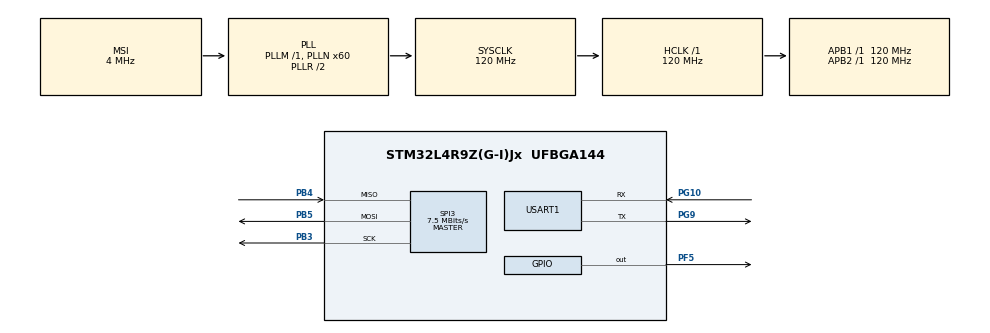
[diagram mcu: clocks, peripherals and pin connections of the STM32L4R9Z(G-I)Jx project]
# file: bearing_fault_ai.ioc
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Mcu.Family=STM32L4
Mcu.Name=STM32L4R9Z(G-I)Jx
Mcu.Package=UFBGA144
NVIC.PriorityGroup=NVIC_PRIORITYGROUP_4
NVIC.SPI3_IRQn=true\:0\:0\:false\:false\:true\:true\:true\:true
NVIC.USART1_IRQn=true\:0\:0\:false\:false\:true\:true\:true\:true
PA13\ (JTMS/SWDIO).Mode=Serial_Wire
PA13\ (JTMS/SWDIO).Signal=SYS_JTMS-SWDIO
PA14\ (JTCK/SWCLK).Mode=Serial_Wire
PA14\ (JTCK/SWCLK).Signal=SYS_JTCK-SWCLK
PB3\ (JTDO/TRACESWO).Mode=Full_Duplex_Master
PB3\ (JTDO/TRACESWO).Signal=SPI3_SCK
PB4\ (NJTRST).Mode=Full_Duplex_Master
PB4\ (NJTRST).Signal=SPI3_MISO
PB5.Mode=Full_Duplex_Master
PB5.Signal=SPI3_MOSI
PC14-OSC32_IN\ (PC14).Mode=LSE-External-Oscillator
PC14-OSC32_IN\ (PC14).Signal=RCC_OSC32_IN
PC15-OSC32_OUT\ (PC15).Mode=LSE-External-Oscillator
PC15-OSC32_OUT\ (PC15).Signal=RCC_OSC32_OUT
PF5.Signal=GPIO_Output
PG10.Mode=Asynchronous
PG10.Signal=USART1_RX
PG9.Mode=Asynchronous
PG9.Signal=USART1_TX
PH0-OSC_IN\ (PH0).Mode=HSE-External-Oscillator
PH0-OSC_IN\ (PH0).Signal=RCC_OSC_IN
PH1-OSC_OUT\ (PH1).Mode=HSE-External-Oscillator
PH1-OSC_OUT\ (PH1).Signal=RCC_OSC_OUT
ProjectManager.HeapSize=0x200
ProjectManager.StackSize=0x400
ProjectManager.TargetToolchain=STM32CubeIDE
RCC.AHBFreq_Value=120000000
RCC.APB1Freq_Value=120000000
RCC.APB1TimFreq_Value=120000000
RCC.APB2Freq_Value=120000000
RCC.APB2TimFreq_Value=120000000
RCC.CortexFreq_Value=120000000
RCC.HCLKFreq_Value=120000000
RCC.HSE_VALUE=8000000
RCC.HSI48_VALUE=48000000
RCC.HSI_VALUE=16000000
RCC.MSI_VALUE=4000000
RCC.PLLN=60
RCC.SYSCLKFreq_VALUE=120000000
RCC.SYSCLKSource=RCC_SYSCLKSOURCE_PLLCLK
RCC.VCOOutputFreq_Value=240000000
SPI3.BaudRatePrescaler=SPI_BAUDRATEPRESCALER_16
SPI3.CalculateBaudRate=7.5 MBits/s
SPI3.DataSize=SPI_DATASIZE_8BIT
SPI3.Direction=SPI_DIRECTION_2LINES
SPI3.Mode=SPI_MODE_MASTER
SPI3.NSSPMode=SPI_NSS_PULSE_DISABLE
SPI3.VirtualType=VM_MASTER
USART1.VirtualMode-Asynchronous=VM_ASYNC
board=custom

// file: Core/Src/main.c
/* USER CODE BEGIN Header */
/**
  ******************************************************************************
  * @file           : main.c
  * @brief          : Main program body
  ******************************************************************************
  * @attention
  *
  * Copyright (c) 2025 STMicroelectronics.
  * All rights reserved.
  *
  * This software is licensed under terms that can be found in the LICENSE file
  * in the root directory of this software component.
  * If no LICENSE file comes with this software, it is provided AS-IS.
  *
  ******************************************************************************
  */
/* USER CODE END Header */
#include "main.h"
#include "spi.h"
#include "usart.h"
#include "gpio.h"

void SystemClock_Config(void);

/* USER CODE BEGIN 0 */
void iis3dwb_read_data_polling(void);

/* USER CODE END 0 */

int main(void)
{

  /* MCU Configuration--------------------------------------------------------*/

  /* Reset of all peripherals, Initializes the Flash interface and the Systick. */
  HAL_Init();

  /* Configure the system clock */
  SystemClock_Config();

  /* Initialize all configured peripherals */
  MX_GPIO_Init();
  MX_SPI3_Init();
  MX_USART1_UART_Init();

  /* Infinite loop */
  /* USER CODE BEGIN WHILE */
  while (1)
  {
	  iis3dwb_read_data_polling();
    /* USER CODE END WHILE */

  }
}

void SystemClock_Config(void)
{
  RCC_OscInitTypeDef RCC_OscInitStruct = {0};
  RCC_ClkInitTypeDef RCC_ClkInitStruct = {0};

  /** Configure the main internal regulator output voltage
  */
  if (HAL_PWREx_ControlVoltageScaling(PWR_REGULATOR_VOLTAGE_SCALE1_BOOST) != HAL_OK)
  {
    Error_Handler();
  }

  /** Initializes the RCC Oscillators according to the specified parameters
  * in the RCC_OscInitTypeDef structure.
  */
  RCC_OscInitStruct.OscillatorType = RCC_OSCILLATORTYPE_MSI;
  RCC_OscInitStruct.MSIState = RCC_MSI_ON;
  RCC_OscInitStruct.MSICalibrationValue = 0;
  RCC_OscInitStruct.MSIClockRange = RCC_MSIRANGE_6;
  RCC_OscInitStruct.PLL.PLLState = RCC_PLL_ON;
  RCC_OscInitStruct.PLL.PLLSource = RCC_PLLSOURCE_MSI;
  RCC_OscInitStruct.PLL.PLLM = 1;
  RCC_OscInitStruct.PLL.PLLN = 60;
  RCC_OscInitStruct.PLL.PLLP = RCC_PLLP_DIV2;
  RCC_OscInitStruct.PLL.PLLQ = RCC_PLLQ_DIV2;
  RCC_OscInitStruct.PLL.PLLR = RCC_PLLR_DIV2;
  if (HAL_RCC_OscConfig(&RCC_OscInitStruct) != HAL_OK)
  {
    Error_Handler();
  }

  /** Initializes the CPU, AHB and APB buses clocks
  */
  RCC_ClkInitStruct.ClockType = RCC_CLOCKTYPE_HCLK|RCC_CLOCKTYPE_SYSCLK
                              |RCC_CLOCKTYPE_PCLK1|RCC_CLOCKTYPE_PCLK2;
  RCC_ClkInitStruct.SYSCLKSource = RCC_SYSCLKSOURCE_PLLCLK;
  RCC_ClkInitStruct.AHBCLKDivider = RCC_SYSCLK_DIV1;
  RCC_ClkInitStruct.APB1CLKDivider = RCC_HCLK_DIV1;
  RCC_ClkInitStruct.APB2CLKDivider = RCC_HCLK_DIV1;

  if (HAL_RCC_ClockConfig(&RCC_ClkInitStruct, FLASH_LATENCY_5) != HAL_OK)
  {
    Error_Handler();
  }
}

void Error_Handler(void)
{
  __disable_irq();
  while (1)
  {
  }
}
